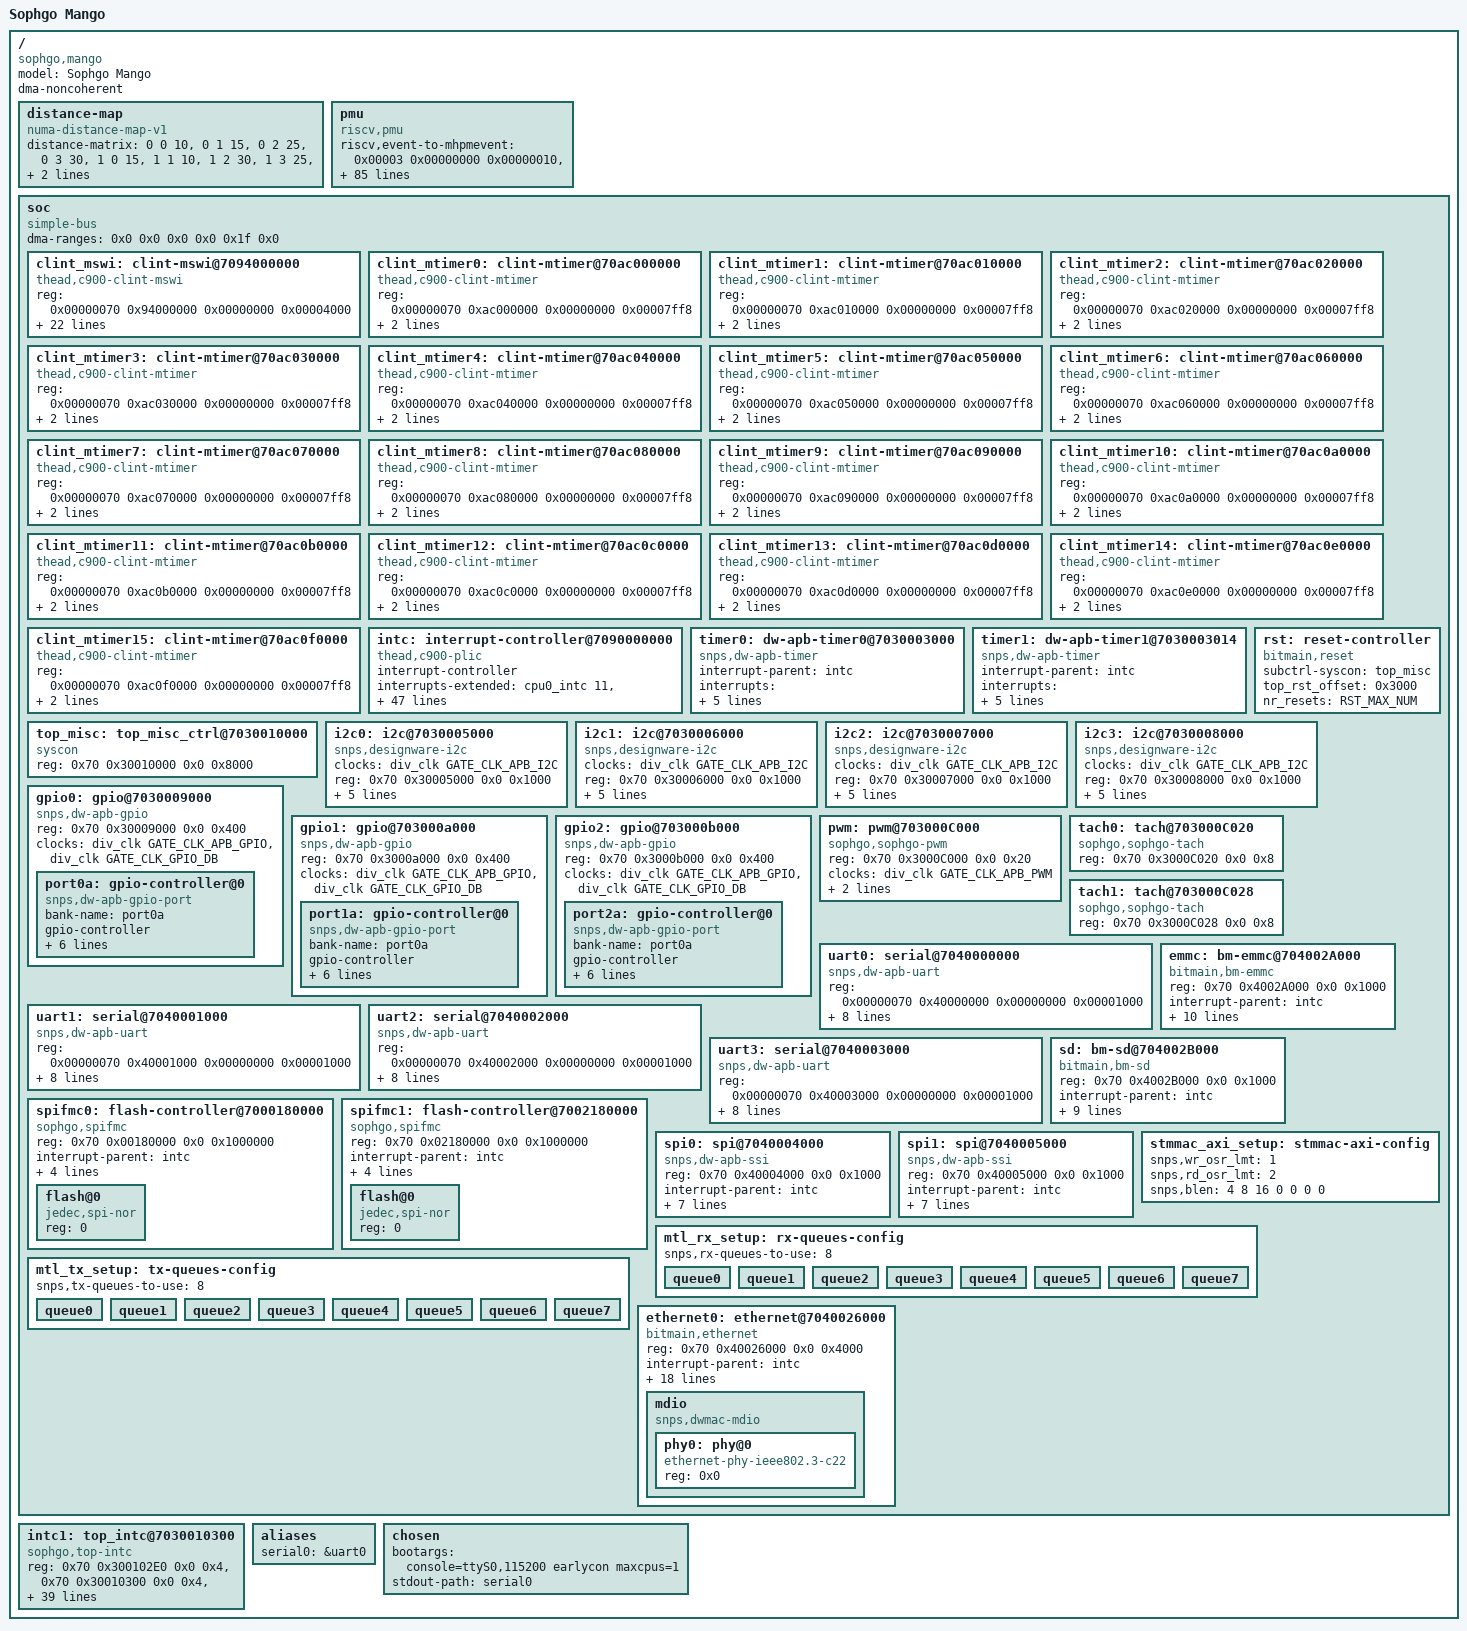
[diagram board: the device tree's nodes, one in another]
/dts-v1/;
#include <dt-bindings/clock/sophgo.h>
#include <dt-bindings/clock/sophgo-mango-clock.h>
#include <dt-bindings/gpio/gpio.h>
#include <dt-bindings/input/input.h>
#include <dt-bindings/reset/sophgo-mango-resets.h>
#include <dt-bindings/interrupt-controller/irq.h>

#include "mango-cpus-socket0.dtsi"
#include "mango-clock-socket0.dtsi"
#include "mango-pinctrl.dtsi"

#define SOC_PERIPHERAL_IRQ(nr)	(nr)

/ {
	model = "Sophgo Mango";
	compatible = "sophgo,mango";
	#address-cells = <2>;
	#size-cells = <2>;
	dma-noncoherent;

	distance-map {
		compatible = "numa-distance-map-v1";
		distance-matrix = <0 0 10>,
				  <0 1 15>,
				  <0 2 25>,
				  <0 3 30>,
				  <1 0 15>,
				  <1 1 10>,
				  <1 2 30>,
				  <1 3 25>,
				  <2 0 25>,
				  <2 1 30>,
				  <2 2 10>,
				  <2 3 15>,
				  <3 0 30>,
				  <3 1 25>,
				  <3 2 15>,
				  <3 3 10>;
	};

	pmu {
		compatible = "riscv,pmu";
		riscv,event-to-mhpmevent =
			<0x00003 0x00000000 0x00000010>,
			<0x00004 0x00000000 0x00000011>,
			<0x00005 0x00000000 0x00000007>,
			<0x00006 0x00000000 0x00000006>,
			<0x00008 0x00000000 0x00000027>,
			<0x00009 0x00000000 0x00000028>,
			<0x10000 0x00000000 0x0000000c>,
			<0x10001 0x00000000 0x0000000d>,
			<0x10002 0x00000000 0x0000000e>,
			<0x10003 0x00000000 0x0000000f>,
			<0x10008 0x00000000 0x00000001>,
			<0x10009 0x00000000 0x00000002>,
			<0x10010 0x00000000 0x00000010>,
			<0x10011 0x00000000 0x00000011>,
			<0x10012 0x00000000 0x00000012>,
			<0x10013 0x00000000 0x00000013>,
			<0x10019 0x00000000 0x00000004>,
			<0x10021 0x00000000 0x00000003>,
			<0x10030 0x00000000 0x0000001c>,
			<0x10031 0x00000000 0x0000001b>;
		riscv,event-to-mhpmcounters =
			<0x00003 0x00003 0xfffffff8>,
			<0x00004 0x00004 0xfffffff8>,
			<0x00005 0x00005 0xfffffff8>,
			<0x00006 0x00006 0xfffffff8>,
			<0x00007 0x00007 0xfffffff8>,
			<0x00008 0x00008 0xfffffff8>,
			<0x00009 0x00009 0xfffffff8>,
			<0x0000a 0x0000a 0xfffffff8>,
			<0x10000 0x10000 0xfffffff8>,
			<0x10001 0x10001 0xfffffff8>,
			<0x10002 0x10002 0xfffffff8>,
			<0x10003 0x10003 0xfffffff8>,
			<0x10008 0x10008 0xfffffff8>,
			<0x10009 0x10009 0xfffffff8>,
			<0x10010 0x10010 0xfffffff8>,
			<0x10011 0x10011 0xfffffff8>,
			<0x10012 0x10012 0xfffffff8>,
			<0x10013 0x10013 0xfffffff8>,
			<0x10019 0x10019 0xfffffff8>,
			<0x10021 0x10021 0xfffffff8>,
			<0x10030 0x10030 0xfffffff8>,
			<0x10031 0x10031 0xfffffff8>;
		riscv,raw-event-to-mhpmcounters =
			<0x00000000 0x00000001 0xffffffff 0xffffffff 0xfffffff8>,
			<0x00000000 0x00000002 0xffffffff 0xffffffff 0xfffffff8>,
			<0x00000000 0x00000003 0xffffffff 0xffffffff 0xfffffff8>,
			<0x00000000 0x00000004 0xffffffff 0xffffffff 0xfffffff8>,
			<0x00000000 0x00000005 0xffffffff 0xffffffff 0xfffffff8>,
			<0x00000000 0x00000006 0xffffffff 0xffffffff 0xfffffff8>,
			<0x00000000 0x00000007 0xffffffff 0xffffffff 0xfffffff8>,
			<0x00000000 0x00000008 0xffffffff 0xffffffff 0xfffffff8>,
			<0x00000000 0x00000009 0xffffffff 0xffffffff 0xfffffff8>,
			<0x00000000 0x0000000a 0xffffffff 0xffffffff 0xfffffff8>,
			<0x00000000 0x0000000b 0xffffffff 0xffffffff 0xfffffff8>,
			<0x00000000 0x0000000c 0xffffffff 0xffffffff 0xfffffff8>,
			<0x00000000 0x0000000d 0xffffffff 0xffffffff 0xfffffff8>,
			<0x00000000 0x0000000e 0xffffffff 0xffffffff 0xfffffff8>,
			<0x00000000 0x0000000f 0xffffffff 0xffffffff 0xfffffff8>,
			<0x00000000 0x00000010 0xffffffff 0xffffffff 0xfffffff8>,
			<0x00000000 0x00000011 0xffffffff 0xffffffff 0xfffffff8>,
			<0x00000000 0x00000012 0xffffffff 0xffffffff 0xfffffff8>,
			<0x00000000 0x00000013 0xffffffff 0xffffffff 0xfffffff8>,
			<0x00000000 0x00000014 0xffffffff 0xffffffff 0xfffffff8>,
			<0x00000000 0x00000015 0xffffffff 0xffffffff 0xfffffff8>,
			<0x00000000 0x00000016 0xffffffff 0xffffffff 0xfffffff8>,
			<0x00000000 0x00000017 0xffffffff 0xffffffff 0xfffffff8>,
			<0x00000000 0x00000018 0xffffffff 0xffffffff 0xfffffff8>,
			<0x00000000 0x00000019 0xffffffff 0xffffffff 0xfffffff8>,
			<0x00000000 0x0000001a 0xffffffff 0xffffffff 0xfffffff8>,
			<0x00000000 0x0000001b 0xffffffff 0xffffffff 0xfffffff8>,
			<0x00000000 0x0000001c 0xffffffff 0xffffffff 0xfffffff8>,
			<0x00000000 0x0000001d 0xffffffff 0xffffffff 0xfffffff8>,
			<0x00000000 0x0000001e 0xffffffff 0xffffffff 0xfffffff8>,
			<0x00000000 0x0000001f 0xffffffff 0xffffffff 0xfffffff8>,
			<0x00000000 0x00000020 0xffffffff 0xffffffff 0xfffffff8>,
			<0x00000000 0x00000021 0xffffffff 0xffffffff 0xfffffff8>,
			<0x00000000 0x00000022 0xffffffff 0xffffffff 0xfffffff8>,
			<0x00000000 0x00000023 0xffffffff 0xffffffff 0xfffffff8>,
			<0x00000000 0x00000024 0xffffffff 0xffffffff 0xfffffff8>,
			<0x00000000 0x00000025 0xffffffff 0xffffffff 0xfffffff8>,
			<0x00000000 0x00000026 0xffffffff 0xffffffff 0xfffffff8>,
			<0x00000000 0x00000027 0xffffffff 0xffffffff 0xfffffff8>,
			<0x00000000 0x00000028 0xffffffff 0xffffffff 0xfffffff8>,
			<0x00000000 0x00000029 0xffffffff 0xffffffff 0xfffffff8>,
			<0x00000000 0x0000002a 0xffffffff 0xffffffff 0xfffffff8>;
	};

	soc: soc {
		#address-cells = <2>;
		#size-cells = <2>;
		compatible = "simple-bus";
		ranges;
		dma-ranges = <0x0 0x0 0x0 0x0 0x1f 0x0>;

		clint_mswi: clint-mswi@7094000000 {
			compatible = "thead,c900-clint-mswi";
			reg = <0x00000070 0x94000000 0x00000000 0x00004000>;
			interrupts-extended = <
				&cpu0_intc 3
				&cpu1_intc 3
				&cpu2_intc 3
				&cpu3_intc 3
				&cpu4_intc 3
				&cpu5_intc 3
				&cpu6_intc 3
				&cpu7_intc 3
				&cpu8_intc 3
				&cpu9_intc 3
				&cpu10_intc 3
				&cpu11_intc 3
				&cpu12_intc 3
				&cpu13_intc 3
				&cpu14_intc 3
				&cpu15_intc 3
				&cpu16_intc 3
				&cpu17_intc 3
				&cpu18_intc 3
				&cpu19_intc 3
				&cpu20_intc 3
				&cpu21_intc 3
				&cpu22_intc 3
				&cpu23_intc 3
				&cpu24_intc 3
				&cpu25_intc 3
				&cpu26_intc 3
				&cpu27_intc 3
				&cpu28_intc 3
				&cpu29_intc 3
				&cpu30_intc 3
				&cpu31_intc 3
				&cpu32_intc 3
				&cpu33_intc 3
				&cpu34_intc 3
				&cpu35_intc 3
				&cpu36_intc 3
				&cpu37_intc 3
				&cpu38_intc 3
				&cpu39_intc 3
				&cpu40_intc 3
				&cpu41_intc 3
				&cpu42_intc 3
				&cpu43_intc 3
				&cpu44_intc 3
				&cpu45_intc 3
				&cpu46_intc 3
				&cpu47_intc 3
				&cpu48_intc 3
				&cpu49_intc 3
				&cpu50_intc 3
				&cpu51_intc 3
				&cpu52_intc 3
				&cpu53_intc 3
				&cpu54_intc 3
				&cpu55_intc 3
				&cpu56_intc 3
				&cpu57_intc 3
				&cpu58_intc 3
				&cpu59_intc 3
				&cpu60_intc 3
				&cpu61_intc 3
				&cpu62_intc 3
				&cpu63_intc 3
				>;
		};

		clint_mtimer0: clint-mtimer@70ac000000 {
			compatible = "thead,c900-clint-mtimer";
			reg = <0x00000070 0xac000000 0x00000000 0x00007ff8>;
			interrupts-extended = <
				&cpu0_intc 7
				&cpu1_intc 7
				&cpu2_intc 7
				&cpu3_intc 7
				>;
		};

		clint_mtimer1: clint-mtimer@70ac010000 {
			compatible = "thead,c900-clint-mtimer";
			reg = <0x00000070 0xac010000 0x00000000 0x00007ff8>;
			interrupts-extended = <
				&cpu4_intc 7
				&cpu5_intc 7
				&cpu6_intc 7
				&cpu7_intc 7
				>;
		};

		clint_mtimer2: clint-mtimer@70ac020000 {
			compatible = "thead,c900-clint-mtimer";
			reg = <0x00000070 0xac020000 0x00000000 0x00007ff8>;
			interrupts-extended = <
				&cpu8_intc 7
				&cpu9_intc 7
				&cpu10_intc 7
				&cpu11_intc 7
				>;
		};

		clint_mtimer3: clint-mtimer@70ac030000 {
			compatible = "thead,c900-clint-mtimer";
			reg = <0x00000070 0xac030000 0x00000000 0x00007ff8>;
			interrupts-extended = <
				&cpu12_intc 7
				&cpu13_intc 7
				&cpu14_intc 7
				&cpu15_intc 7
				>;
		};

		clint_mtimer4: clint-mtimer@70ac040000 {
			compatible = "thead,c900-clint-mtimer";
			reg = <0x00000070 0xac040000 0x00000000 0x00007ff8>;
			interrupts-extended = <
				&cpu16_intc 7
				&cpu17_intc 7
				&cpu18_intc 7
				&cpu19_intc 7
				>;
		};

		clint_mtimer5: clint-mtimer@70ac050000 {
			compatible = "thead,c900-clint-mtimer";
			reg = <0x00000070 0xac050000 0x00000000 0x00007ff8>;
			interrupts-extended = <
				&cpu20_intc 7
				&cpu21_intc 7
				&cpu22_intc 7
				&cpu23_intc 7
				>;
		};

		clint_mtimer6: clint-mtimer@70ac060000 {
			compatible = "thead,c900-clint-mtimer";
			reg = <0x00000070 0xac060000 0x00000000 0x00007ff8>;
			interrupts-extended = <
				&cpu24_intc 7
				&cpu25_intc 7
				&cpu26_intc 7
				&cpu27_intc 7
				>;
		};

		clint_mtimer7: clint-mtimer@70ac070000 {
			compatible = "thead,c900-clint-mtimer";
			reg = <0x00000070 0xac070000 0x00000000 0x00007ff8>;
			interrupts-extended = <
				&cpu28_intc 7
				&cpu29_intc 7
				&cpu30_intc 7
				&cpu31_intc 7
				>;
		};

		clint_mtimer8: clint-mtimer@70ac080000 {
			compatible = "thead,c900-clint-mtimer";
			reg = <0x00000070 0xac080000 0x00000000 0x00007ff8>;
			interrupts-extended = <
				&cpu32_intc 7
				&cpu33_intc 7
				&cpu34_intc 7
				&cpu35_intc 7
				>;
		};

		clint_mtimer9: clint-mtimer@70ac090000 {
			compatible = "thead,c900-clint-mtimer";
			reg = <0x00000070 0xac090000 0x00000000 0x00007ff8>;
			interrupts-extended = <
				&cpu36_intc 7
				&cpu37_intc 7
				&cpu38_intc 7
				&cpu39_intc 7
				>;
		};

		clint_mtimer10: clint-mtimer@70ac0a0000 {
			compatible = "thead,c900-clint-mtimer";
			reg = <0x00000070 0xac0a0000 0x00000000 0x00007ff8>;
			interrupts-extended = <
				&cpu40_intc 7
				&cpu41_intc 7
				&cpu42_intc 7
				&cpu43_intc 7
				>;
		};

		clint_mtimer11: clint-mtimer@70ac0b0000 {
			compatible = "thead,c900-clint-mtimer";
			reg = <0x00000070 0xac0b0000 0x00000000 0x00007ff8>;
			interrupts-extended = <
				&cpu44_intc 7
				&cpu45_intc 7
				&cpu46_intc 7
				&cpu47_intc 7
				>;
		};

		clint_mtimer12: clint-mtimer@70ac0c0000 {
			compatible = "thead,c900-clint-mtimer";
			reg = <0x00000070 0xac0c0000 0x00000000 0x00007ff8>;
			interrupts-extended = <
				&cpu48_intc 7
				&cpu49_intc 7
				&cpu50_intc 7
				&cpu51_intc 7
				>;
		};

		clint_mtimer13: clint-mtimer@70ac0d0000 {
			compatible = "thead,c900-clint-mtimer";
			reg = <0x00000070 0xac0d0000 0x00000000 0x00007ff8>;
			interrupts-extended = <
				&cpu52_intc 7
				&cpu53_intc 7
				&cpu54_intc 7
				&cpu55_intc 7
				>;
		};

		clint_mtimer14: clint-mtimer@70ac0e0000 {
			compatible = "thead,c900-clint-mtimer";
			reg = <0x00000070 0xac0e0000 0x00000000 0x00007ff8>;
			interrupts-extended = <
				&cpu56_intc 7
				&cpu57_intc 7
				&cpu58_intc 7
				&cpu59_intc 7
				>;
		};

		clint_mtimer15: clint-mtimer@70ac0f0000 {
			compatible = "thead,c900-clint-mtimer";
			reg = <0x00000070 0xac0f0000 0x00000000 0x00007ff8>;
			interrupts-extended = <
				&cpu60_intc 7
				&cpu61_intc 7
				&cpu62_intc 7
				&cpu63_intc 7
				>;
		};

		intc: interrupt-controller@7090000000 {
			#address-cells = <0>;
			#interrupt-cells = <2>;
			compatible = "thead,c900-plic";
			interrupt-controller;
			interrupts-extended = <
				&cpu0_intc  11 &cpu0_intc  9
				&cpu1_intc  11 &cpu1_intc  9
				&cpu2_intc  11 &cpu2_intc  9
				&cpu3_intc  11 &cpu3_intc  9
				&cpu4_intc  11 &cpu4_intc  9
				&cpu5_intc  11 &cpu5_intc  9
				&cpu6_intc  11 &cpu6_intc  9
				&cpu7_intc  11 &cpu7_intc  9
				&cpu8_intc  11 &cpu8_intc  9
				&cpu9_intc  11 &cpu9_intc  9
				&cpu10_intc  11 &cpu10_intc  9
				&cpu11_intc  11 &cpu11_intc  9
				&cpu12_intc  11 &cpu12_intc  9
				&cpu13_intc  11 &cpu13_intc  9
				&cpu14_intc  11 &cpu14_intc  9
				&cpu15_intc  11 &cpu15_intc  9
				&cpu16_intc  11 &cpu16_intc  9
				&cpu17_intc  11 &cpu17_intc  9
				&cpu18_intc  11 &cpu18_intc  9
				&cpu19_intc  11 &cpu19_intc  9
				&cpu20_intc  11 &cpu20_intc  9
				&cpu21_intc  11 &cpu21_intc  9
				&cpu22_intc  11 &cpu22_intc  9
				&cpu23_intc  11 &cpu23_intc  9
				&cpu24_intc  11 &cpu24_intc  9
				&cpu25_intc  11 &cpu25_intc  9
				&cpu26_intc  11 &cpu26_intc  9
				&cpu27_intc  11 &cpu27_intc  9
				&cpu28_intc  11 &cpu28_intc  9
				&cpu29_intc  11 &cpu29_intc  9
				&cpu30_intc  11 &cpu30_intc  9
				&cpu31_intc  11 &cpu31_intc  9
				&cpu32_intc  11 &cpu32_intc  9
				&cpu33_intc  11 &cpu33_intc  9
				&cpu34_intc  11 &cpu34_intc  9
				&cpu35_intc  11 &cpu35_intc  9
				&cpu36_intc  11 &cpu36_intc  9
				&cpu37_intc  11 &cpu37_intc  9
				&cpu38_intc  11 &cpu38_intc  9
				&cpu39_intc  11 &cpu39_intc  9
				&cpu40_intc  11 &cpu40_intc  9
				&cpu41_intc  11 &cpu41_intc  9
				&cpu42_intc  11 &cpu42_intc  9
				&cpu43_intc  11 &cpu43_intc  9
				&cpu44_intc  11 &cpu44_intc  9
				&cpu45_intc  11 &cpu45_intc  9
				&cpu46_intc  11 &cpu46_intc  9
				&cpu47_intc  11 &cpu47_intc  9
				&cpu48_intc  11 &cpu48_intc  9
				&cpu49_intc  11 &cpu49_intc  9
				&cpu50_intc  11 &cpu50_intc  9
				&cpu51_intc  11 &cpu51_intc  9
				&cpu52_intc  11 &cpu52_intc  9
				&cpu53_intc  11 &cpu53_intc  9
				&cpu54_intc  11 &cpu54_intc  9
				&cpu55_intc  11 &cpu55_intc  9
				&cpu56_intc  11 &cpu56_intc  9
				&cpu57_intc  11 &cpu57_intc  9
				&cpu58_intc  11 &cpu58_intc  9
				&cpu59_intc  11 &cpu59_intc  9
				&cpu60_intc  11 &cpu60_intc  9
				&cpu61_intc  11 &cpu61_intc  9
				&cpu62_intc  11 &cpu62_intc  9
				&cpu63_intc  11 &cpu63_intc  9
				>;
			reg = <0x00000070 0x90000000 0x00000000 0x04000000>;
			reg-names = "control";
			riscv,max-priority = <7>;
			riscv,ndev = <224>;
		};

		timer0: dw-apb-timer0@7030003000 {
			compatible = "snps,dw-apb-timer";
			interrupt-parent = <&intc>;
			interrupts = <SOC_PERIPHERAL_IRQ(100) IRQ_TYPE_LEVEL_HIGH>;
			reg = <0x70 0x30003000 0x0 0x14>;
			clocks = <&div_clk GATE_CLK_TIMER1>,
				 <&div_clk GATE_CLK_APB_TIMER>;
			clock-names = "timer", "pclk";
			clk-drv-rating = <300>;
		};

		timer1: dw-apb-timer1@7030003014 {
			compatible = "snps,dw-apb-timer";
			interrupt-parent = <&intc>;
			interrupts = <SOC_PERIPHERAL_IRQ(100) IRQ_TYPE_LEVEL_HIGH>;
			reg = <0x70 0x30003014 0x0 0x10>;
			clocks = <&div_clk GATE_CLK_TIMER2>,
				 <&div_clk GATE_CLK_APB_TIMER>;
			clock-names = "timer", "pclk";
			clk-drv-rating = <300>;
		};

		top_misc: top_misc_ctrl@7030010000 {
			compatible = "syscon";
			reg = <0x70 0x30010000 0x0 0x8000>;
		};

		rst: reset-controller {
			#reset-cells = <1>;
			compatible = "bitmain,reset";
			subctrl-syscon = <&top_misc>;
			top_rst_offset = <0x3000>;
			nr_resets = <RST_MAX_NUM>;
		};

		i2c0: i2c@7030005000 {
			#address-cells = <1>;
			#size-cells = <0>;
			compatible = "snps,designware-i2c";
			clocks = <&div_clk GATE_CLK_APB_I2C>;
			clock-names = "clk_gate_apb_i2c";
			reg = <0x70 0x30005000 0x0 0x1000>;
			interrupt-parent = <&intc>;
			interrupts = <SOC_PERIPHERAL_IRQ(101) IRQ_TYPE_LEVEL_HIGH>;
			clock-frequency = <100000>;
			resets = <&rst RST_I2C0>;
			reset-names = "i2c0";
		};

		i2c1: i2c@7030006000 {
			#address-cells = <1>;
			#size-cells = <0>;
			compatible = "snps,designware-i2c";
			clocks = <&div_clk GATE_CLK_APB_I2C>;
			clock-names = "clk_gate_apb_i2c";
			reg = <0x70 0x30006000 0x0 0x1000>;
			interrupt-parent = <&intc>;
			interrupts = <SOC_PERIPHERAL_IRQ(102) IRQ_TYPE_LEVEL_HIGH>;
			clock-frequency = <100000>;
			resets = <&rst RST_I2C1>;
			reset-names = "i2c1";
		};

		i2c2: i2c@7030007000 {
			#address-cells = <1>;
			#size-cells = <0>;
			compatible = "snps,designware-i2c";
			clocks = <&div_clk GATE_CLK_APB_I2C>;
			clock-names = "clk_gate_apb_i2c";
			reg = <0x70 0x30007000 0x0 0x1000>;
			interrupt-parent = <&intc>;
			interrupts = <SOC_PERIPHERAL_IRQ(103) IRQ_TYPE_LEVEL_HIGH>;
			clock-frequency = <100000>;
			resets = <&rst RST_I2C2>;
			reset-names = "i2c2";
		};

		i2c3: i2c@7030008000 {
			#address-cells = <1>;
			#size-cells = <0>;
			compatible = "snps,designware-i2c";
			clocks = <&div_clk GATE_CLK_APB_I2C>;
			clock-names = "clk_gate_apb_i2c";
			reg = <0x70 0x30008000 0x0 0x1000>;
			interrupt-parent = <&intc>;
			interrupts = <SOC_PERIPHERAL_IRQ(104) IRQ_TYPE_LEVEL_HIGH>;
			clock-frequency = <100000>;
			resets = <&rst RST_I2C3>;
			reset-names = "i2c3";
		};

		gpio0: gpio@7030009000 {
			compatible = "snps,dw-apb-gpio";
			reg = <0x70 0x30009000 0x0 0x400>;
			#address-cells = <1>;
			#size-cells = <0>;
			clocks = <&div_clk GATE_CLK_APB_GPIO>,
				 <&div_clk GATE_CLK_GPIO_DB>;
			clock-names = "bus", "db";

			port0a: gpio-controller@0 {
				compatible = "snps,dw-apb-gpio-port";
				bank-name = "port0a";
				gpio-controller;
				#gpio-cells = <2>;
				snps,nr-gpios = <32>;
				reg = <0>;
				interrupt-controller;
				#interrupt-cells = <2>;
				interrupt-parent = <&intc>;
				interrupts = <SOC_PERIPHERAL_IRQ(96) IRQ_TYPE_LEVEL_HIGH>;
			};
		};

		gpio1: gpio@703000a000 {
			compatible = "snps,dw-apb-gpio";
			reg = <0x70 0x3000a000 0x0 0x400>;
			#address-cells = <1>;
			#size-cells = <0>;
			clocks = <&div_clk GATE_CLK_APB_GPIO>,
				 <&div_clk GATE_CLK_GPIO_DB>;
			clock-names = "bus", "db";

			port1a: gpio-controller@0 {
				compatible = "snps,dw-apb-gpio-port";
				bank-name = "port0a";
				gpio-controller;
				#gpio-cells = <2>;
				snps,nr-gpios = <32>;
				reg = <0>;
				interrupt-controller;
				#interrupt-cells = <2>;
				interrupt-parent = <&intc>;
				interrupts = <SOC_PERIPHERAL_IRQ(97) IRQ_TYPE_LEVEL_HIGH>;
			};
		};

		gpio2: gpio@703000b000 {
			compatible = "snps,dw-apb-gpio";
			reg = <0x70 0x3000b000 0x0 0x400>;
			#address-cells = <1>;
			#size-cells = <0>;
			clocks = <&div_clk GATE_CLK_APB_GPIO>,
				 <&div_clk GATE_CLK_GPIO_DB>;
			clock-names = "bus", "db";

			port2a: gpio-controller@0 {
				compatible = "snps,dw-apb-gpio-port";
				bank-name = "port0a";
				gpio-controller;
				#gpio-cells = <2>;
				snps,nr-gpios = <32>;
				reg = <0>;
				interrupt-controller;
				#interrupt-cells = <2>;
				interrupt-parent = <&intc>;
				interrupts = <SOC_PERIPHERAL_IRQ(98) IRQ_TYPE_LEVEL_HIGH>;
			};
		};

		pwm: pwm@703000C000 {
			compatible = "sophgo,sophgo-pwm";
			reg = <0x70 0x3000C000 0x0 0x20>;
			clocks = <&div_clk GATE_CLK_APB_PWM>;
			clock-names = "clk_gate_apb_pwm";
			#pwm-cells = <2>;
			pwm-num = <2>;
			no-polarity;
		};

		tach0: tach@703000C020 {
			compatible = "sophgo,sophgo-tach";
			reg = <0x70 0x3000C020 0x0 0x8>;
		};

		tach1: tach@703000C028 {
			compatible = "sophgo,sophgo-tach";
			reg = <0x70 0x3000C028 0x0 0x8>;
		};

		uart0: serial@7040000000 {
			compatible = "snps,dw-apb-uart";
			reg = <0x00000070 0x40000000 0x00000000 0x00001000>;
			interrupt-parent = <&intc>;
			interrupts = <SOC_PERIPHERAL_IRQ(112) IRQ_TYPE_LEVEL_HIGH>;
			clock-frequency = <500000000>;
			clocks = <&div_clk GATE_CLK_UART_500M>,
				 <&div_clk GATE_CLK_APB_UART>;
			clock-names = "baudclk", "apb_pclk";
			reg-shift = <2>;
			reg-io-width = <4>;
		};

		uart1: serial@7040001000 {
			compatible = "snps,dw-apb-uart";
			reg = <0x00000070 0x40001000 0x00000000 0x00001000>;
			interrupt-parent = <&intc>;
			interrupts = <SOC_PERIPHERAL_IRQ(113) IRQ_TYPE_LEVEL_HIGH>;
			clock-frequency = <500000000>;
			clocks = <&div_clk GATE_CLK_UART_500M>,
				 <&div_clk GATE_CLK_APB_UART>;
			clock-names = "baudclk", "apb_pclk";
			reg-shift = <2>;
			reg-io-width = <4>;
		};

		uart2: serial@7040002000 {
			compatible = "snps,dw-apb-uart";
			reg = <0x00000070 0x40002000 0x00000000 0x00001000>;
			interrupt-parent = <&intc>;
			interrupts = <SOC_PERIPHERAL_IRQ(114) IRQ_TYPE_LEVEL_HIGH>;
			clock-frequency = <500000000>;
			clocks = <&div_clk GATE_CLK_UART_500M>,
				 <&div_clk GATE_CLK_APB_UART>;
			clock-names = "baudclk", "apb_pclk";
			reg-shift = <2>;
			reg-io-width = <4>;
		};

		uart3: serial@7040003000 {
			compatible = "snps,dw-apb-uart";
			reg = <0x00000070 0x40003000 0x00000000 0x00001000>;
			interrupt-parent = <&intc>;
			interrupts = <SOC_PERIPHERAL_IRQ(115) IRQ_TYPE_LEVEL_HIGH>;
			clock-frequency = <500000000>;
			clocks = <&div_clk GATE_CLK_UART_500M>,
				 <&div_clk GATE_CLK_APB_UART>;
			clock-names = "baudclk", "apb_pclk";
			reg-shift = <2>;
			reg-io-width = <4>;
		};

		emmc: bm-emmc@704002A000 {
			compatible = "bitmain,bm-emmc";
			reg = <0x70 0x4002A000 0x0 0x1000>;
			reg-names = "core_mem";
			interrupt-parent = <&intc>;
			interrupts = <SOC_PERIPHERAL_IRQ(134) IRQ_TYPE_LEVEL_HIGH>;
			bus-width = <4>;
			non-removable;
			no-sdio;
			no-sd;
			resets = <&rst RST_EMMC>;
			reset-names = "emmc";
			clocks =
				<&div_clk GATE_CLK_EMMC_100M>,
				<&div_clk GATE_CLK_AXI_EMMC>,
				<&div_clk GATE_CLK_100K_EMMC>;
			clock-names =
				"clk_gate_emmc",
				"clk_gate_axi_emmc",
				"clk_gate_100k_emmc";
		};

		sd: bm-sd@704002B000 {
			compatible = "bitmain,bm-sd";
			reg = <0x70 0x4002B000 0x0 0x1000>;
			reg-names = "core_mem";
			interrupt-parent = <&intc>;
			interrupts = <SOC_PERIPHERAL_IRQ(136) IRQ_TYPE_LEVEL_HIGH>;
			bus-width = <4>;
			no-sdio;
			no-mmc;
			resets = <&rst RST_SD>;
			reset-names = "sdio";
			clocks =
				<&div_clk GATE_CLK_SD_100M>,
				<&div_clk GATE_CLK_AXI_SD>,
				<&div_clk GATE_CLK_100K_SD>;
			clock-names =
				"clk_gate_sd",
				"clk_gate_axi_sd",
				"clk_gate_100k_sd";
		};

		spifmc0: flash-controller@7000180000 {
			compatible = "sophgo,spifmc";
			reg = <0x70 0x00180000 0x0 0x1000000>;
			reg-names = "memory";
			#address-cells = <1>;
			#size-cells = <0>;
			interrupt-parent = <&intc>;
			interrupts = <SOC_PERIPHERAL_IRQ(108) IRQ_TYPE_LEVEL_HIGH>;
			clock-frequency = <100000000>;
			clocks = <&div_clk GATE_CLK_AHB_SF>;
			flash@0 {
				reg = <0>;
				compatible = "jedec,spi-nor";
			};
		};

		spifmc1: flash-controller@7002180000 {
			compatible = "sophgo,spifmc";
			reg = <0x70 0x02180000 0x0 0x1000000>;
			reg-names = "memory";
			#address-cells = <1>;
			#size-cells = <0>;
			interrupt-parent = <&intc>;
			interrupts = <SOC_PERIPHERAL_IRQ(109) IRQ_TYPE_LEVEL_HIGH>;
			clock-frequency = <100000000>;
			clocks = <&div_clk GATE_CLK_AHB_SF>;
			flash@0 {
				reg = <0>;
				compatible = "jedec,spi-nor";
			};
		};

                spi0: spi@7040004000 {
			compatible = "snps,dw-apb-ssi";
			#address-cells = <1>;
			#size-cells = <0>;
			reg = <0x70 0x40004000 0x0 0x1000>;
			interrupt-parent = <&intc>;
			interrupts = <SOC_PERIPHERAL_IRQ(110) IRQ_TYPE_LEVEL_HIGH>;
			clocks = <&div_clk GATE_CLK_APB_SPI>,
			          <&div_clk GATE_CLK_SYSDMA_AXI>;
			clock-frequency = <250000000>;
			resets = <&rst RST_SPI0>;
			reset-names = "spi0";
			num-cs = <2>;
			status = "okay";
                };

                spi1: spi@7040005000 {
			compatible = "snps,dw-apb-ssi";
			#address-cells = <1>;
			#size-cells = <0>;
			reg = <0x70 0x40005000 0x0 0x1000>;
			interrupt-parent = <&intc>;
			interrupts = <SOC_PERIPHERAL_IRQ(111) IRQ_TYPE_LEVEL_HIGH>;
			clocks = <&div_clk GATE_CLK_APB_SPI>,
			           <&div_clk GATE_CLK_SYSDMA_AXI>;
			clock-frequency = <250000000>;
			resets = <&rst RST_SPI1>;
			reset-names = "spi1";
			num-cs = <2>;
			status = "okay";
                };

		stmmac_axi_setup: stmmac-axi-config {
			snps,wr_osr_lmt = <1>;
			snps,rd_osr_lmt = <2>;
			snps,blen = <4 8 16 0 0 0 0>;
		};

		mtl_rx_setup: rx-queues-config {
			snps,rx-queues-to-use = <8>;
			queue0 {};
			queue1 {};
			queue2 {};
			queue3 {};
			queue4 {};
			queue5 {};
			queue6 {};
			queue7 {};
		};

		mtl_tx_setup: tx-queues-config {
			snps,tx-queues-to-use = <8>;
			queue0 {};
			queue1 {};
			queue2 {};
			queue3 {};
			queue4 {};
			queue5 {};
			queue6 {};
			queue7 {};
		};

		ethernet0: ethernet@7040026000 {
			compatible = "bitmain,ethernet";
			reg = <0x70 0x40026000 0x0 0x4000>;
			interrupt-parent = <&intc>;
			interrupts = <SOC_PERIPHERAL_IRQ(132) IRQ_TYPE_LEVEL_HIGH>;
			interrupt-names = "macirq";
			clock-names = "clk_tx", "gate_clk_tx", "stmmaceth", "ptp_ref", "gate_clk_ref";
			clocks = <&div_clk DIV_CLK_FPLL_TX_ETH0>,
				   <&div_clk GATE_CLK_TX_ETH0>,
				   <&div_clk GATE_CLK_AXI_ETH0>,
				   <&div_clk GATE_CLK_PTP_REF_I_ETH0>,
				   <&div_clk GATE_CLK_REF_ETH0>;

			/* no hash filter and perfect filter support */
			snps,multicast-filter-bins = <0>;
			snps,perfect-filter-entries = <1>;

			snps,txpbl = <32>;
			snps,rxpbl = <32>;
			snps,aal;

			snps,axi-config = <&stmmac_axi_setup>;
			snps,mtl-rx-config = <&mtl_rx_setup>;
			snps,mtl-tx-config = <&mtl_tx_setup>;

			phy-mode = "rgmii-txid";
			phy-reset-gpios = <&port0a 27 0>;
			phy-handle = <&phy0>;
			mdio {
				#address-cells = <0x1>;
				#size-cells = <0x0>;
				compatible = "snps,dwmac-mdio";
				phy0: phy@0 {
					compatible = "ethernet-phy-ieee802.3-c22";
					device_type = "ethernet-phy";
					reg = <0x0>;
				};
			};
		};
	};

	intc1: top_intc@7030010300 {
		compatible = "sophgo,top-intc";
		reg = <0x70 0x300102E0 0x0 0x4>,
		      <0x70 0x30010300 0x0 0x4>,
		      <0x70 0x30010304 0x0 0x4>;
		reg-names = "sta", "set", "clr";
		reg-bitwidth = <32>;
		top_intc_id = <0>;
		interrupt-controller;
		#interrupt-cells = <0x1>; // only applies to child node
		for-msi;

		interrupt-parent = <&intc>;
		interrupts = <SOC_PERIPHERAL_IRQ(64) IRQ_TYPE_LEVEL_HIGH>,
			     <SOC_PERIPHERAL_IRQ(65) IRQ_TYPE_LEVEL_HIGH>,
			     <SOC_PERIPHERAL_IRQ(66) IRQ_TYPE_LEVEL_HIGH>,
			     <SOC_PERIPHERAL_IRQ(67) IRQ_TYPE_LEVEL_HIGH>,
			     <SOC_PERIPHERAL_IRQ(68) IRQ_TYPE_LEVEL_HIGH>,
			     <SOC_PERIPHERAL_IRQ(69) IRQ_TYPE_LEVEL_HIGH>,
			     <SOC_PERIPHERAL_IRQ(70) IRQ_TYPE_LEVEL_HIGH>,
			     <SOC_PERIPHERAL_IRQ(71) IRQ_TYPE_LEVEL_HIGH>,
			     <SOC_PERIPHERAL_IRQ(72) IRQ_TYPE_LEVEL_HIGH>,
			     <SOC_PERIPHERAL_IRQ(73) IRQ_TYPE_LEVEL_HIGH>,
			     <SOC_PERIPHERAL_IRQ(74) IRQ_TYPE_LEVEL_HIGH>,
			     <SOC_PERIPHERAL_IRQ(75) IRQ_TYPE_LEVEL_HIGH>,
			     <SOC_PERIPHERAL_IRQ(76) IRQ_TYPE_LEVEL_HIGH>,
			     <SOC_PERIPHERAL_IRQ(77) IRQ_TYPE_LEVEL_HIGH>,
			     <SOC_PERIPHERAL_IRQ(78) IRQ_TYPE_LEVEL_HIGH>,
			     <SOC_PERIPHERAL_IRQ(79) IRQ_TYPE_LEVEL_HIGH>,
			     <SOC_PERIPHERAL_IRQ(80) IRQ_TYPE_LEVEL_HIGH>,
			     <SOC_PERIPHERAL_IRQ(81) IRQ_TYPE_LEVEL_HIGH>,
			     <SOC_PERIPHERAL_IRQ(82) IRQ_TYPE_LEVEL_HIGH>,
			     <SOC_PERIPHERAL_IRQ(83) IRQ_TYPE_LEVEL_HIGH>,
			     <SOC_PERIPHERAL_IRQ(84) IRQ_TYPE_LEVEL_HIGH>,
			     <SOC_PERIPHERAL_IRQ(85) IRQ_TYPE_LEVEL_HIGH>,
			     <SOC_PERIPHERAL_IRQ(86) IRQ_TYPE_LEVEL_HIGH>,
			     <SOC_PERIPHERAL_IRQ(87) IRQ_TYPE_LEVEL_HIGH>,
			     <SOC_PERIPHERAL_IRQ(88) IRQ_TYPE_LEVEL_HIGH>,
			     <SOC_PERIPHERAL_IRQ(89) IRQ_TYPE_LEVEL_HIGH>,
			     <SOC_PERIPHERAL_IRQ(90) IRQ_TYPE_LEVEL_HIGH>,
			     <SOC_PERIPHERAL_IRQ(91) IRQ_TYPE_LEVEL_HIGH>,
			     <SOC_PERIPHERAL_IRQ(92) IRQ_TYPE_LEVEL_HIGH>,
			     <SOC_PERIPHERAL_IRQ(93) IRQ_TYPE_LEVEL_HIGH>,
			     <SOC_PERIPHERAL_IRQ(94) IRQ_TYPE_LEVEL_HIGH>,
			     <SOC_PERIPHERAL_IRQ(95) IRQ_TYPE_LEVEL_HIGH>;
		interrupt-names = "msi0",  "msi1",  "msi2",  "msi3",
				  "msi4",  "msi5",  "msi6",  "msi7",
				  "msi8",  "msi9",  "msi10", "msi11",
				  "msi12", "msi13", "msi14", "msi15",
				  "msi16", "msi17", "msi18", "msi19",
				  "msi20", "msi21", "msi22", "msi23",
				  "msi24", "msi25", "msi26", "msi27",
				  "msi28", "msi29", "msi30", "msi31";

	};

	aliases {
		serial0 = &uart0;
	};

	chosen: chosen {
		bootargs = "console=ttyS0,115200 earlycon maxcpus=1";
		stdout-path = "serial0";
	};
};
